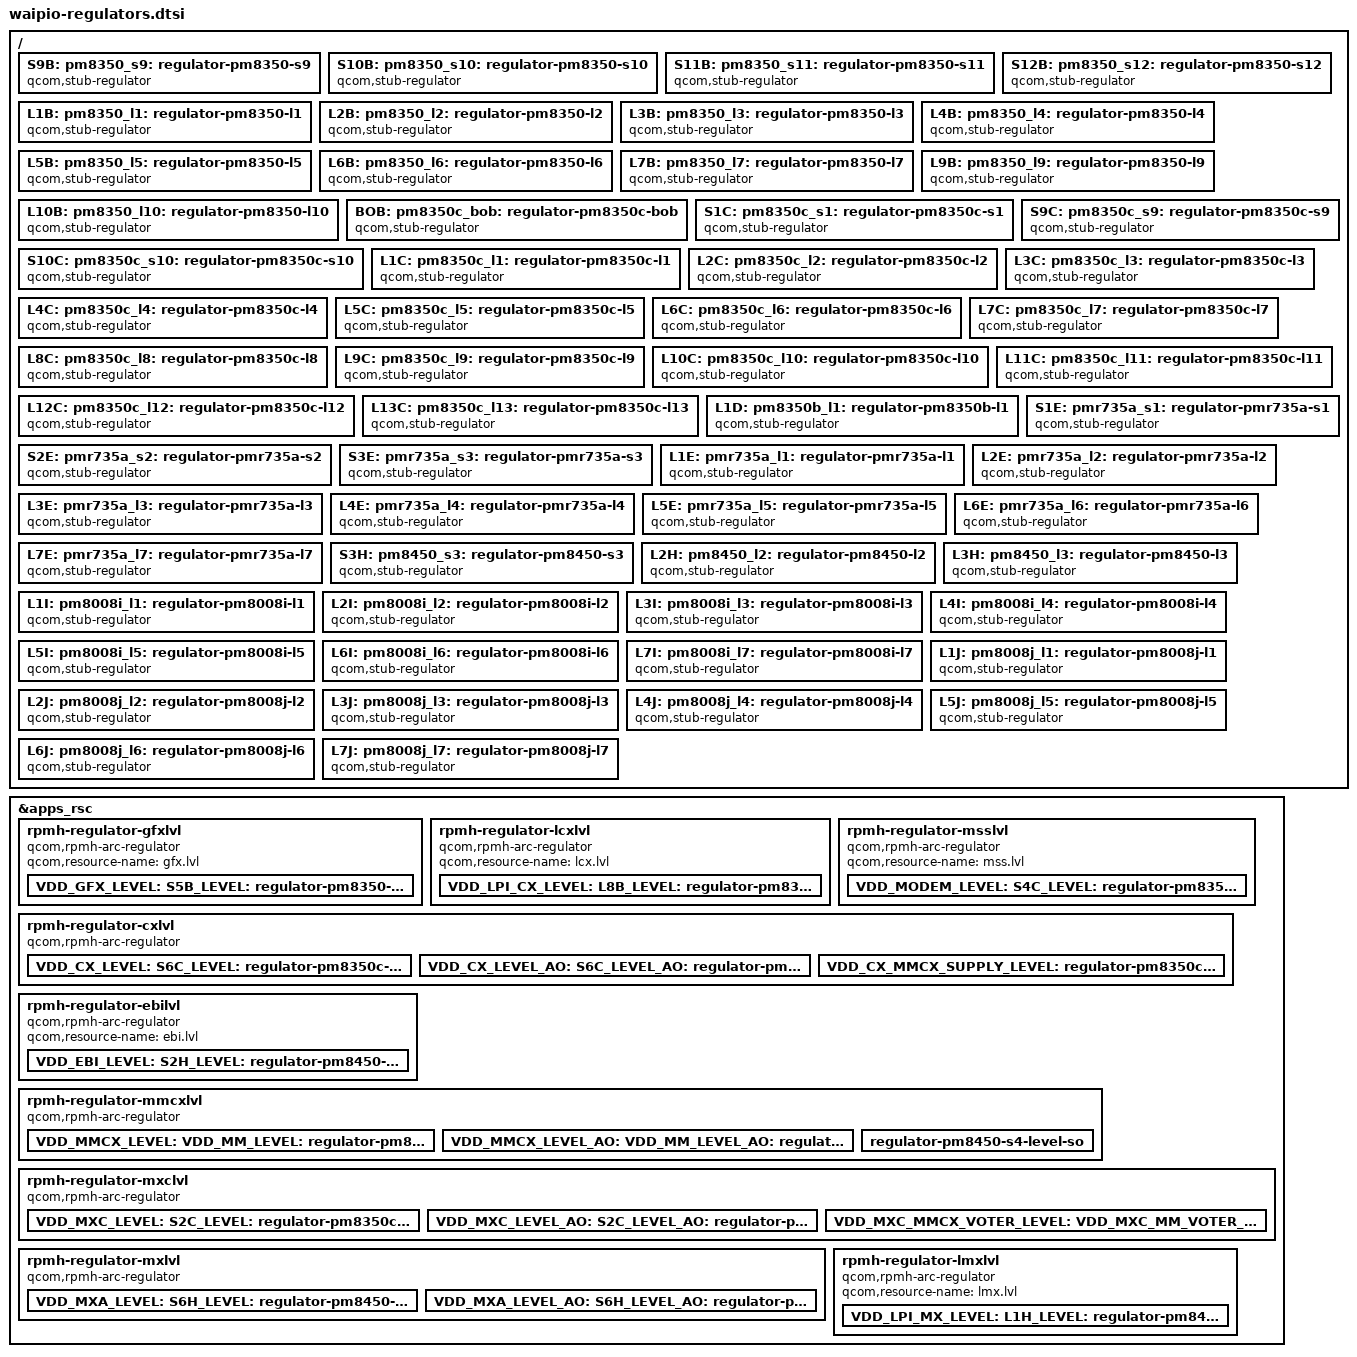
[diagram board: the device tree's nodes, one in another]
#include <dt-bindings/regulator/qcom,rpmh-regulator-levels.h>

&apps_rsc {
	rpmh-regulator-gfxlvl {
		compatible = "qcom,rpmh-arc-regulator";
		qcom,resource-name = "gfx.lvl";
		VDD_GFX_LEVEL: S5B_LEVEL:
		pm8350_s5_level: regulator-pm8350-s5-level {
			regulator-name = "pm8350_s5_level";
			qcom,set = <RPMH_REGULATOR_SET_ALL>;
			regulator-min-microvolt =
				<RPMH_REGULATOR_LEVEL_RETENTION>;
			regulator-max-microvolt =
				<RPMH_REGULATOR_LEVEL_MAX>;
			qcom,init-voltage-level =
				<RPMH_REGULATOR_LEVEL_RETENTION>;
		};
	};

	rpmh-regulator-lcxlvl {
		compatible = "qcom,rpmh-arc-regulator";
		qcom,resource-name = "lcx.lvl";
		VDD_LPI_CX_LEVEL: L8B_LEVEL:
		pm8350_l8_level: regulator-pm8350-l8-level {
			regulator-name = "pm8350_l8_level";
			qcom,set = <RPMH_REGULATOR_SET_ALL>;
			regulator-min-microvolt =
				<RPMH_REGULATOR_LEVEL_RETENTION>;
			regulator-max-microvolt =
				<RPMH_REGULATOR_LEVEL_MAX>;
			qcom,init-voltage-level =
				<RPMH_REGULATOR_LEVEL_RETENTION>;
		};
	};

	rpmh-regulator-msslvl {
		compatible = "qcom,rpmh-arc-regulator";
		qcom,resource-name = "mss.lvl";
		VDD_MODEM_LEVEL: S4C_LEVEL:
		pm8350c_s4_level: regulator-pm8350c-s4-level {
			regulator-name = "pm8350c_s4_level";
			qcom,set = <RPMH_REGULATOR_SET_ALL>;
			regulator-min-microvolt =
				<RPMH_REGULATOR_LEVEL_RETENTION>;
			regulator-max-microvolt =
				<RPMH_REGULATOR_LEVEL_MAX>;
			qcom,init-voltage-level =
				<RPMH_REGULATOR_LEVEL_RETENTION>;
		};
	};

	rpmh-regulator-cxlvl {
		compatible = "qcom,rpmh-arc-regulator";
		qcom,resource-name = "cx.lvl";
		proxy-supply = <&VDD_CX_LEVEL>;

		VDD_CX_LEVEL: S6C_LEVEL:
		pm8350c_s6_level: regulator-pm8350c-s6-level {
			regulator-name = "pm8350c_s6_level";
			qcom,set = <RPMH_REGULATOR_SET_ALL>;
			regulator-min-microvolt =
				<RPMH_REGULATOR_LEVEL_RETENTION>;
			regulator-max-microvolt =
				<RPMH_REGULATOR_LEVEL_MAX>;
			qcom,init-voltage-level =
				<RPMH_REGULATOR_LEVEL_TURBO>;
			qcom,proxy-consumer-enable;
			qcom,proxy-consumer-voltage =
				<RPMH_REGULATOR_LEVEL_TURBO
				 RPMH_REGULATOR_LEVEL_MAX>;
		};

		VDD_CX_LEVEL_AO: S6C_LEVEL_AO:
		pm8350c_s6_level_ao: regulator-pm8350c-s6-level-ao {
			regulator-name = "pm8350c_s6_level_ao";
			qcom,set = <RPMH_REGULATOR_SET_ACTIVE>;
			regulator-min-microvolt =
				<RPMH_REGULATOR_LEVEL_RETENTION>;
			regulator-max-microvolt =
				<RPMH_REGULATOR_LEVEL_MAX>;
			qcom,init-voltage-level =
				<RPMH_REGULATOR_LEVEL_RETENTION>;
		};

		VDD_CX_MMCX_SUPPLY_LEVEL: regulator-pm8350c-s6-mmcx-sup-level {
			regulator-name = "pm8350c_s6_mmcx_sup_level";
			qcom,set = <RPMH_REGULATOR_SET_ALL>;
			regulator-min-microvolt =
				<RPMH_REGULATOR_LEVEL_MIN_SVS>;
			regulator-max-microvolt =
				<RPMH_REGULATOR_LEVEL_MAX>;
			qcom,init-voltage-level =
				<RPMH_REGULATOR_LEVEL_MIN_SVS>;
		};
	};

	rpmh-regulator-ebilvl {
		compatible = "qcom,rpmh-arc-regulator";
		qcom,resource-name = "ebi.lvl";
		VDD_EBI_LEVEL: S2H_LEVEL:
		pm8450_s2_level: regulator-pm8450-s2-level {
			regulator-name = "pm8450_s2_level";
			qcom,set = <RPMH_REGULATOR_SET_ALL>;
			regulator-min-microvolt =
				<RPMH_REGULATOR_LEVEL_RETENTION>;
			regulator-max-microvolt =
				<RPMH_REGULATOR_LEVEL_MAX>;
			qcom,init-voltage-level =
				<RPMH_REGULATOR_LEVEL_RETENTION>;
		};
	};

	rpmh-regulator-mmcxlvl {
		compatible = "qcom,rpmh-arc-regulator";
		qcom,resource-name = "mmcx.lvl";
		proxy-supply = <&VDD_MMCX_LEVEL>;

		VDD_MMCX_LEVEL: VDD_MM_LEVEL: S4H_LEVEL:
		pm8450_s4_level: regulator-pm8450-s4-level {
			regulator-name = "pm8450_s4_level";
			qcom,set = <RPMH_REGULATOR_SET_ALL>;
			pm8450_s4_level-parent-supply =
				<&VDD_CX_MMCX_SUPPLY_LEVEL>;
			regulator-min-microvolt =
				<RPMH_REGULATOR_LEVEL_LOW_SVS>;
			regulator-max-microvolt =
				<RPMH_REGULATOR_LEVEL_MAX>;
			qcom,init-voltage-level =
				<RPMH_REGULATOR_LEVEL_TURBO>;
			qcom,proxy-consumer-enable;
			qcom,proxy-consumer-voltage =
				<RPMH_REGULATOR_LEVEL_TURBO
				 RPMH_REGULATOR_LEVEL_MAX>;
		};

		VDD_MMCX_LEVEL_AO: VDD_MM_LEVEL_AO: S4H_LEVEL_AO:
		pm8450_s4_level_ao: regulator-pm8450-s4-level-ao {
			regulator-name = "pm8450_s4_level_ao";
			qcom,set = <RPMH_REGULATOR_SET_ACTIVE>;
			regulator-min-microvolt =
				<RPMH_REGULATOR_LEVEL_LOW_SVS>;
			regulator-max-microvolt =
				<RPMH_REGULATOR_LEVEL_MAX>;
			qcom,init-voltage-level =
				<RPMH_REGULATOR_LEVEL_LOW_SVS>;
		};

		regulator-pm8450-s4-level-so {
			regulator-name = "pm8450_s4_level_so";
			qcom,set = <RPMH_REGULATOR_SET_SLEEP>;
			regulator-min-microvolt =
				<RPMH_REGULATOR_LEVEL_LOW_SVS>;
			regulator-max-microvolt =
				<RPMH_REGULATOR_LEVEL_MAX>;
			qcom,init-voltage-level =
				<RPMH_REGULATOR_LEVEL_LOW_SVS>;
		};
	};

	rpmh-regulator-mxclvl {
		compatible = "qcom,rpmh-arc-regulator";
		qcom,resource-name = "mxc.lvl";
		proxy-supply = <&VDD_MXC_LEVEL>;

		VDD_MXC_LEVEL: S2C_LEVEL:
		pm8350c_s2_level: regulator-pm8350c-s2-level {
			regulator-name = "pm8350c_s2_level";
			qcom,set = <RPMH_REGULATOR_SET_ALL>;
			regulator-min-microvolt =
				<RPMH_REGULATOR_LEVEL_RETENTION>;
			regulator-max-microvolt =
				<RPMH_REGULATOR_LEVEL_MAX>;
			qcom,init-voltage-level =
				<RPMH_REGULATOR_LEVEL_TURBO>;
			qcom,proxy-consumer-enable;
			qcom,proxy-consumer-voltage =
				<RPMH_REGULATOR_LEVEL_TURBO
				 RPMH_REGULATOR_LEVEL_MAX>;
		};

		VDD_MXC_LEVEL_AO: S2C_LEVEL_AO:
		pm8350c_s2_level_ao: regulator-pm8350c-s2-level-ao {
			regulator-name = "pm8350c_s2_level_ao";
			qcom,set = <RPMH_REGULATOR_SET_ACTIVE>;
			regulator-min-microvolt =
				<RPMH_REGULATOR_LEVEL_RETENTION>;
			regulator-max-microvolt =
				<RPMH_REGULATOR_LEVEL_MAX>;
			qcom,init-voltage-level =
				<RPMH_REGULATOR_LEVEL_RETENTION>;
		};

		VDD_MXC_MMCX_VOTER_LEVEL: VDD_MXC_MM_VOTER_LEVEL:
		VDD_MM_MXC_VOTER_LEVEL:
		regulator-pm8350c-s2-mmcx-voter-level {
			regulator-name = "pm8350c_s2_mmcx_voter_level";
			vin-supply = <&VDD_MMCX_LEVEL>;
			qcom,set = <RPMH_REGULATOR_SET_ALL>;
			regulator-min-microvolt =
				<RPMH_REGULATOR_LEVEL_MIN_SVS>;
			regulator-max-microvolt =
				<RPMH_REGULATOR_LEVEL_MAX>;
			qcom,init-voltage-level =
				<RPMH_REGULATOR_LEVEL_MIN_SVS>;
		};
	};

	rpmh-regulator-mxlvl {
		compatible = "qcom,rpmh-arc-regulator";
		qcom,resource-name = "mx.lvl";
		proxy-supply = <&VDD_MXA_LEVEL>;

		VDD_MXA_LEVEL: S6H_LEVEL:
		pm8450_s6_level: regulator-pm8450-s6-level {
			regulator-name = "pm8450_s6_level";
			qcom,set = <RPMH_REGULATOR_SET_ALL>;
			regulator-min-microvolt =
				<RPMH_REGULATOR_LEVEL_RETENTION>;
			regulator-max-microvolt =
				<RPMH_REGULATOR_LEVEL_MAX>;
			qcom,init-voltage-level =
				<RPMH_REGULATOR_LEVEL_TURBO>;
			qcom,proxy-consumer-enable;
			qcom,proxy-consumer-voltage =
				<RPMH_REGULATOR_LEVEL_TURBO
				 RPMH_REGULATOR_LEVEL_MAX>;
		};

		VDD_MXA_LEVEL_AO: S6H_LEVEL_AO:
		pm8450_s6_level_ao: regulator-pm8450-s6-level-ao {
			regulator-name = "pm8450_s6_level_ao";
			qcom,set = <RPMH_REGULATOR_SET_ACTIVE>;
			regulator-min-microvolt =
				<RPMH_REGULATOR_LEVEL_RETENTION>;
			regulator-max-microvolt =
				<RPMH_REGULATOR_LEVEL_MAX>;
			qcom,init-voltage-level =
				<RPMH_REGULATOR_LEVEL_RETENTION>;
		};
	};

	rpmh-regulator-lmxlvl {
		compatible = "qcom,rpmh-arc-regulator";
		qcom,resource-name = "lmx.lvl";
		VDD_LPI_MX_LEVEL: L1H_LEVEL:
		pm8450_l1_level: regulator-pm8450-l1-level {
			regulator-name = "pm8450_l1_level";
			qcom,set = <RPMH_REGULATOR_SET_ALL>;
			regulator-min-microvolt =
				<RPMH_REGULATOR_LEVEL_RETENTION>;
			regulator-max-microvolt =
				<RPMH_REGULATOR_LEVEL_MAX>;
			qcom,init-voltage-level =
				<RPMH_REGULATOR_LEVEL_RETENTION>;
		};
	};
};

/ {
	S9B: pm8350_s9: regulator-pm8350-s9 {
		compatible = "qcom,stub-regulator";
		regulator-name = "pm8350_s9";
		regulator-min-microvolt = <464000>;
		regulator-max-microvolt = <800000>;
	};

	S10B: pm8350_s10: regulator-pm8350-s10 {
		compatible = "qcom,stub-regulator";
		regulator-name = "pm8350_s10";
		regulator-min-microvolt = <1800000>;
		regulator-max-microvolt = <1800000>;
	};

	S11B: pm8350_s11: regulator-pm8350-s11 {
		compatible = "qcom,stub-regulator";
		regulator-name = "pm8350_s11";
		regulator-min-microvolt = <864000>;
		regulator-max-microvolt = <1068000>;
	};

	S12B: pm8350_s12: regulator-pm8350-s12 {
		compatible = "qcom,stub-regulator";
		regulator-name = "pm8350_s12";
		regulator-min-microvolt = <1256000>;
		regulator-max-microvolt = <1256000>;
	};

	L1B: pm8350_l1: regulator-pm8350-l1 {
		compatible = "qcom,stub-regulator";
		regulator-name = "pm8350_l1";
		regulator-min-microvolt = <832000>;
		regulator-max-microvolt = <920000>;
		qcom,hpm-min-load = <30000>;
	};

	L2B: pm8350_l2: regulator-pm8350-l2 {
		compatible = "qcom,stub-regulator";
		regulator-name = "pm8350_l2";
		regulator-min-microvolt = <3000000>;
		regulator-max-microvolt = <3296000>;
		qcom,hpm-min-load = <10000>;
	};

	L3B: pm8350_l3: regulator-pm8350-l3 {
		compatible = "qcom,stub-regulator";
		regulator-name = "pm8350_l3";
		regulator-min-microvolt = <872000>;
		regulator-max-microvolt = <968000>;
		qcom,hpm-min-load = <30000>;
	};

	L4B: pm8350_l4: regulator-pm8350-l4 {
		compatible = "qcom,stub-regulator";
		regulator-name = "pm8350_l4";
		regulator-min-microvolt = <752000>;
		regulator-max-microvolt = <832000>;
		qcom,hpm-min-load = <30000>;
	};

	L5B: pm8350_l5: regulator-pm8350-l5 {
		compatible = "qcom,stub-regulator";
		regulator-name = "pm8350_l5";
		regulator-min-microvolt = <880000>;
		regulator-max-microvolt = <912000>;
		qcom,hpm-min-load = <30000>;
	};

	L6B: pm8350_l6: regulator-pm8350-l6 {
		compatible = "qcom,stub-regulator";
		regulator-name = "pm8350_l6";
		regulator-min-microvolt = <1200000>;
		regulator-max-microvolt = <1248000>;
		qcom,hpm-min-load = <30000>;
	};

	L7B: pm8350_l7: regulator-pm8350-l7 {
		compatible = "qcom,stub-regulator";
		regulator-name = "pm8350_l7";
		regulator-min-microvolt = <2400000>;
		regulator-max-microvolt = <3600000>;
		qcom,hpm-min-load = <10000>;
	};

	L9B: pm8350_l9: regulator-pm8350-l9 {
		compatible = "qcom,stub-regulator";
		regulator-name = "pm8350_l9";
		regulator-min-microvolt = <1144000>;
		regulator-max-microvolt = <1256000>;
		qcom,hpm-min-load = <30000>;
	};

	L10B: pm8350_l10: regulator-pm8350-l10 {
		compatible = "qcom,stub-regulator";
		regulator-name = "pm8350_l10";
		regulator-min-microvolt = <1176000>;
		regulator-max-microvolt = <1400000>;
		qcom,hpm-min-load = <30000>;
	};

	BOB: pm8350c_bob: regulator-pm8350c-bob {
		compatible = "qcom,stub-regulator";
		regulator-name = "pm8350c_bob";
		regulator-min-microvolt = <3008000>;
		regulator-max-microvolt = <3960000>;
	};

	S1C: pm8350c_s1: regulator-pm8350c-s1 {
		compatible = "qcom,stub-regulator";
		regulator-name = "pm8350c_s1";
		regulator-min-microvolt = <1824000>;
		regulator-max-microvolt = <1900000>;
	};

	S9C: pm8350c_s9: regulator-pm8350c-s9 {
		compatible = "qcom,stub-regulator";
		regulator-name = "pm8350c_s9";
		regulator-min-microvolt = <676000>;
		regulator-max-microvolt = <800000>;
	};

	S10C: pm8350c_s10: regulator-pm8350c-s10 {
		compatible = "qcom,stub-regulator";
		regulator-name = "pm8350c_s10";
		regulator-min-microvolt = <1052000>;
		regulator-max-microvolt = <1120000>;
	};

	L1C: pm8350c_l1: regulator-pm8350c-l1 {
		compatible = "qcom,stub-regulator";
		regulator-name = "pm8350c_l1";
		regulator-min-microvolt = <1080000>;
		regulator-max-microvolt = <1800000>;
		qcom,hpm-min-load = <10000>;
	};

	L2C: pm8350c_l2: regulator-pm8350c-l2 {
		compatible = "qcom,stub-regulator";
		regulator-name = "pm8350c_l2";
		regulator-min-microvolt = <1624000>;
		regulator-max-microvolt = <1976000>;
		qcom,hpm-min-load = <10000>;
	};

	L3C: pm8350c_l3: regulator-pm8350c-l3 {
		compatible = "qcom,stub-regulator";
		regulator-name = "pm8350c_l3";
		regulator-min-microvolt = <2704000>;
		regulator-max-microvolt = <3600000>;
		qcom,hpm-min-load = <10000>;
	};

	L4C: pm8350c_l4: regulator-pm8350c-l4 {
		compatible = "qcom,stub-regulator";
		regulator-name = "pm8350c_l4";
		regulator-min-microvolt = <1656000>;
		regulator-max-microvolt = <3296000>;
		qcom,hpm-min-load = <10000>;
	};

	L5C: pm8350c_l5: regulator-pm8350c-l5 {
		compatible = "qcom,stub-regulator";
		regulator-name = "pm8350c_l5";
		regulator-min-microvolt = <1656000>;
		regulator-max-microvolt = <3296000>;
		qcom,hpm-min-load = <10000>;
	};

	L6C: pm8350c_l6: regulator-pm8350c-l6 {
		compatible = "qcom,stub-regulator";
		regulator-name = "pm8350c_l6";
		regulator-min-microvolt = <1760000>;
		regulator-max-microvolt = <2960000>;
		qcom,hpm-min-load = <10000>;
	};

	L7C: pm8350c_l7: regulator-pm8350c-l7 {
		compatible = "qcom,stub-regulator";
		regulator-name = "pm8350c_l7";
		regulator-min-microvolt = <3000000>;
		regulator-max-microvolt = <3600000>;
		qcom,hpm-min-load = <10000>;
	};

	L8C: pm8350c_l8: regulator-pm8350c-l8 {
		compatible = "qcom,stub-regulator";
		regulator-name = "pm8350c_l8";
		regulator-min-microvolt = <1712000>;
		regulator-max-microvolt = <1944000>;
		qcom,hpm-min-load = <10000>;
	};

	L9C: pm8350c_l9: regulator-pm8350c-l9 {
		compatible = "qcom,stub-regulator";
		regulator-name = "pm8350c_l9";
		regulator-min-microvolt = <2704000>;
		regulator-max-microvolt = <3600000>;
		qcom,hpm-min-load = <10000>;
	};

	L10C: pm8350c_l10: regulator-pm8350c-l10 {
		compatible = "qcom,stub-regulator";
		regulator-name = "pm8350c_l10";
		regulator-min-microvolt = <1200000>;
		regulator-max-microvolt = <1200000>;
		qcom,hpm-min-load = <30000>;
	};

	L11C: pm8350c_l11: regulator-pm8350c-l11 {
		compatible = "qcom,stub-regulator";
		regulator-name = "pm8350c_l11";
		regulator-min-microvolt = <2504000>;
		regulator-max-microvolt = <2504000>;
		qcom,hpm-min-load = <10000>;
	};

	L12C: pm8350c_l12: regulator-pm8350c-l12 {
		compatible = "qcom,stub-regulator";
		regulator-name = "pm8350c_l12";
		regulator-min-microvolt = <1656000>;
		regulator-max-microvolt = <1944000>;
		qcom,hpm-min-load = <10000>;
	};

	L13C: pm8350c_l13: regulator-pm8350c-l13 {
		compatible = "qcom,stub-regulator";
		regulator-name = "pm8350c_l13";
		regulator-min-microvolt = <2704000>;
		regulator-max-microvolt = <3296000>;
		qcom,hpm-min-load = <10000>;
	};

	L1D: pm8350b_l1: regulator-pm8350b-l1 {
		compatible = "qcom,stub-regulator";
		regulator-name = "pm8350b_l1";
		regulator-min-microvolt = <1104000>;
		regulator-max-microvolt = <1296000>;
		qcom,hpm-min-load = <30000>;
	};

	S1E: pmr735a_s1: regulator-pmr735a-s1 {
		compatible = "qcom,stub-regulator";
		regulator-name = "pmr735a_s1";
		regulator-min-microvolt = <1256000>;
		regulator-max-microvolt = <1256000>;
	};

	S2E: pmr735a_s2: regulator-pmr735a-s2 {
		compatible = "qcom,stub-regulator";
		regulator-name = "pmr735a_s2";
		regulator-min-microvolt = <852000>;
		regulator-max-microvolt = <852000>;
	};

	S3E: pmr735a_s3: regulator-pmr735a-s3 {
		compatible = "qcom,stub-regulator";
		regulator-name = "pmr735a_s3";
		regulator-min-microvolt = <2000000>;
		regulator-max-microvolt = <2400000>;
	};

	L1E: pmr735a_l1: regulator-pmr735a-l1 {
		compatible = "qcom,stub-regulator";
		regulator-name = "pmr735a_l1";
		regulator-min-microvolt = <832000>;
		regulator-max-microvolt = <912000>;
		qcom,hpm-min-load = <30000>;
	};

	L2E: pmr735a_l2: regulator-pmr735a-l2 {
		compatible = "qcom,stub-regulator";
		regulator-name = "pmr735a_l2";
		regulator-min-microvolt = <1200000>;
		regulator-max-microvolt = <1236000>;
		qcom,hpm-min-load = <30000>;
	};

	L3E: pmr735a_l3: regulator-pmr735a-l3 {
		compatible = "qcom,stub-regulator";
		regulator-name = "pmr735a_l3";
		regulator-min-microvolt = <1200000>;
		regulator-max-microvolt = <1200000>;
		qcom,hpm-min-load = <30000>;
	};

	L4E: pmr735a_l4: regulator-pmr735a-l4 {
		compatible = "qcom,stub-regulator";
		regulator-name = "pmr735a_l4";
		regulator-min-microvolt = <1704000>;
		regulator-max-microvolt = <1776000>;
		qcom,hpm-min-load = <10000>;
	};

	L5E: pmr735a_l5: regulator-pmr735a-l5 {
		compatible = "qcom,stub-regulator";
		regulator-name = "pmr735a_l5";
		regulator-min-microvolt = <760000>;
		regulator-max-microvolt = <824000>;
		qcom,hpm-min-load = <30000>;
	};

	L6E: pmr735a_l6: regulator-pmr735a-l6 {
		compatible = "qcom,stub-regulator";
		regulator-name = "pmr735a_l6";
		regulator-min-microvolt = <720000>;
		regulator-max-microvolt = <800000>;
		qcom,hpm-min-load = <30000>;
	};

	L7E: pmr735a_l7: regulator-pmr735a-l7 {
		compatible = "qcom,stub-regulator";
		regulator-name = "pmr735a_l7";
		regulator-min-microvolt = <2600000>;
		regulator-max-microvolt = <3400000>;
		qcom,hpm-min-load = <10000>;
	};

	S3H: pm8450_s3: regulator-pm8450-s3 {
		compatible = "qcom,stub-regulator";
		regulator-name = "pm8450_s3";
		regulator-min-microvolt = <472000>;
		regulator-max-microvolt = <568000>;
	};

	L2H: pm8450_l2: regulator-pm8450-l2 {
		compatible = "qcom,stub-regulator";
		regulator-name = "pm8450_l2";
		regulator-min-microvolt = <872000>;
		regulator-max-microvolt = <920000>;
		qcom,hpm-min-load = <30000>;
	};

	L3H: pm8450_l3: regulator-pm8450-l3 {
		compatible = "qcom,stub-regulator";
		regulator-name = "pm8450_l3";
		regulator-min-microvolt = <866000>;
		regulator-max-microvolt = <958000>;
		qcom,hpm-min-load = <30000>;
	};

	L1I: pm8008i_l1: regulator-pm8008i-l1 {
		compatible = "qcom,stub-regulator";
		regulator-name = "pm8008i_l1";
		regulator-min-microvolt = <1104000>;
		regulator-max-microvolt = <1104000>;
		qcom,hpm-min-load = <30000>;
	};

	L2I: pm8008i_l2: regulator-pm8008i-l2 {
		compatible = "qcom,stub-regulator";
		regulator-name = "pm8008i_l2";
		regulator-min-microvolt = <952000>;
		regulator-max-microvolt = <1144000>;
		qcom,hpm-min-load = <30000>;
	};

	L3I: pm8008i_l3: regulator-pm8008i-l3 {
		compatible = "qcom,stub-regulator";
		regulator-name = "pm8008i_l3";
		regulator-min-microvolt = <2704000>;
		regulator-max-microvolt = <3000000>;
		qcom,hpm-min-load = <10000>;
	};

	L4I: pm8008i_l4: regulator-pm8008i-l4 {
		compatible = "qcom,stub-regulator";
		regulator-name = "pm8008i_l4";
		regulator-min-microvolt = <2704000>;
		regulator-max-microvolt = <2896000>;
		qcom,hpm-min-load = <10000>;
	};

	L5I: pm8008i_l5: regulator-pm8008i-l5 {
		compatible = "qcom,stub-regulator";
		regulator-name = "pm8008i_l5";
		regulator-min-microvolt = <1800000>;
		regulator-max-microvolt = <1800000>;
		qcom,hpm-min-load = <10000>;
	};

	L6I: pm8008i_l6: regulator-pm8008i-l6 {
		compatible = "qcom,stub-regulator";
		regulator-name = "pm8008i_l6";
		regulator-min-microvolt = <2704000>;
		regulator-max-microvolt = <2896000>;
		qcom,hpm-min-load = <10000>;
	};

	L7I: pm8008i_l7: regulator-pm8008i-l7 {
		compatible = "qcom,stub-regulator";
		regulator-name = "pm8008i_l7";
		regulator-min-microvolt = <2704000>;
		regulator-max-microvolt = <3000000>;
		qcom,hpm-min-load = <10000>;
	};

	L1J: pm8008j_l1: regulator-pm8008j-l1 {
		compatible = "qcom,stub-regulator";
		regulator-name = "pm8008j_l1";
		regulator-min-microvolt = <1000000>;
		regulator-max-microvolt = <1200000>;
		qcom,hpm-min-load = <30000>;
	};

	L2J: pm8008j_l2: regulator-pm8008j-l2 {
		compatible = "qcom,stub-regulator";
		regulator-name = "pm8008j_l2";
		regulator-min-microvolt = <952000>;
		regulator-max-microvolt = <1144000>;
		qcom,hpm-min-load = <30000>;
	};

	L3J: pm8008j_l3: regulator-pm8008j-l3 {
		compatible = "qcom,stub-regulator";
		regulator-name = "pm8008j_l3";
		regulator-min-microvolt = <1800000>;
		regulator-max-microvolt = <1800000>;
		qcom,hpm-min-load = <10000>;
	};

	L4J: pm8008j_l4: regulator-pm8008j-l4 {
		compatible = "qcom,stub-regulator";
		regulator-name = "pm8008j_l4";
		regulator-min-microvolt = <1704000>;
		regulator-max-microvolt = <1896000>;
		qcom,hpm-min-load = <10000>;
	};

	L5J: pm8008j_l5: regulator-pm8008j-l5 {
		compatible = "qcom,stub-regulator";
		regulator-name = "pm8008j_l5";
		regulator-min-microvolt = <2704000>;
		regulator-max-microvolt = <2896000>;
		qcom,hpm-min-load = <10000>;
	};

	L6J: pm8008j_l6: regulator-pm8008j-l6 {
		compatible = "qcom,stub-regulator";
		regulator-name = "pm8008j_l6";
		regulator-min-microvolt = <2800000>;
		regulator-max-microvolt = <2800000>;
		qcom,hpm-min-load = <10000>;
	};

	L7J: pm8008j_l7: regulator-pm8008j-l7 {
		compatible = "qcom,stub-regulator";
		regulator-name = "pm8008j_l7";
		regulator-min-microvolt = <3000000>;
		regulator-max-microvolt = <3304000>;
		qcom,hpm-min-load = <10000>;
	};
};
